# V32F20x_CM33 register map
File version: 1.0.3
CPU: CM33 r0p4, little endian, MPU, FPU, DSP, 3 interrupt priority bits, 8 SAU regions
Registers are 32-bit, read-write, reset 0x0 unless marked. A register's access mark holds for its fields unless they carry their own. Offsets are from the block's base; [hi:lo] are bit positions; {n}, {i} and the like mark numbered series.

## ETMR0 — ETMR0 Peripheral Interface
Base 0x40050800
Same registers: ETMR1 0x40051000, SEC_ETMR0 0x50050800, SEC_ETMR1 0x50051000
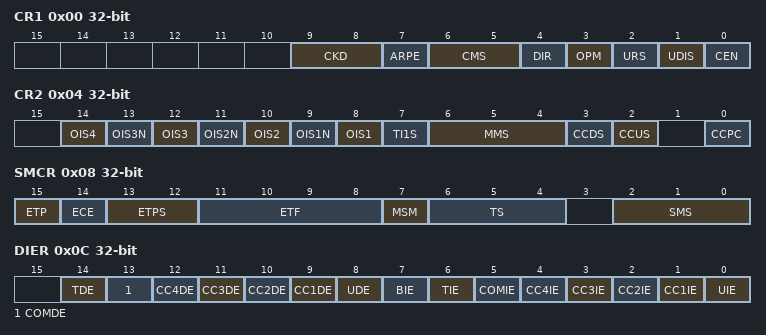
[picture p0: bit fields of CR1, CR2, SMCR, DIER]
0x00 CR1 — ETMR control register 1
  [9:8] CKD — This bit field indicates the division ratio between the timer clock CK_INT frequency and the dead time and sampling clock tDTS used by the dead time generators and the digital filters ETR TIx
  [7] ARPE — 0: ETMR_ARR register is not buffered
  [6:5] CMS — 00 Edge aligned mode
  [4] DIR — 0: Counter used as upcounter
  [3] OPM — 0: Counter is not stopped at update event
  [2] URS — This bit is set and cleared by software to select the UEV event sources
  [1] UDIS — This bit is set and cleared by software to enable disable UEV event generation
  [0] CEN — 0: Counter disabled
0x04 CR2 — ETMR control register 1
  [14] OIS4 — refer to OIS1 bit
  [13] OIS3N — refer to OIS1N bit
  [12] OIS3 — refer to OIS1 bit
  [11] OIS2N — refer to OIS1N bit
  [10] OIS2 — refer to OIS1 bit
  [9] OIS1N — 0: OC1N=0 after a dead-time when MOE=0
  [8] OIS1 — 0 OC1 0 after a dead time if OC1N is implemented when MOE 0
  [7] TI1S — 0: The ETMR_CH1 pin is connected to TI1 input
  [6:4] MMS — These bits allow to select the information to be sent in master mode to slave timers for synchronization TRGO
  [3] CCDS — 0: CCx DMA request sent when CCx event occurs
  [2] CCUS — 0 When capture compare control bits are preloaded CCPC 1 they are updated by setting the COMG bit only
  [0] CCPC — 0: CCxE, CCxNE and OCxM bits are not preloaded
0x08 SMCR — slave mode control register
  [15] ETP — This bit selects whether ETR or ETR is used for trigger operations
  [14] ECE — This bit enables External clock mode 2.
  [13:12] ETPS — External trigger signal ETRP frequency must be at most 1 4 of ETMRCLK frequency
  [11:8] ETF — This bit field then defines the frequency used to sample ETRP signal and the length of the digital filter applied to ETRP
  [7] MSM — 0: No action
  [6:4] TS — This bit field selects the trigger input to be used to synchronize the counter
  [2:0] SMS — When external signals are selected the active edge of the trigger signal TRGI is linked to the polarity selected on the external input see Input Control register and Control register description
0x0C DIER — DMA/interrupt enable register
  [14] TDE — 0: Trigger DMA request disabled
  [13] COMDE — 0: COM DMA request disabled
  [n+8] CC{n}DE (n=1..4) — 0: CC{n} DMA request disabled
  [8] UDE — 0: Update DMA request disabled
  [7] BIE — 0: Break interrupt disabled
  [6] TIE — 0: Trigger interrupt disabled
  [5] COMIE — 0: COM interrupt disabled
  [n] CC{n}IE (n=1..4) — 0: CC{n} interrupt disabled
  [0] UIE — Update interrupt enable
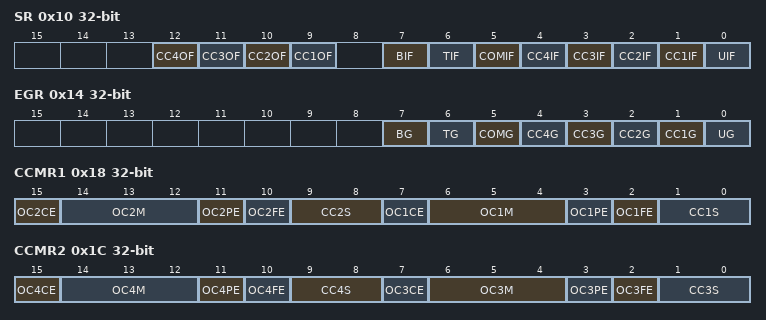
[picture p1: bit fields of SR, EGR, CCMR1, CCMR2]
0x10 SR — status register
  [12] CC4OF — refer to CC1OF description
  [11] CC3OF — refer to CC1OF description
  [10] CC2OF — refer to CC1OF description
  [9] CC1OF — This flag is set by hardware only when the corresponding channel is configured in input capture mode
  [7] BIF — This flag is set by hardware as soon as the break input goes active
  [6] TIF — This flag is set by hardware on trigger event active edge detected on TRGI input when the slave mode controller is enabled in all modes but gated mode both edges in case gated mode is selected
  [5] COMIF — This flag is set by hardware on COM event when Capture compare Control bits CCxE CCxNE OCxM have been updated
  [4] CC4IF — refer to CC1IF description
  [3] CC3IF — refer to CC1IF description
  [2] CC2IF — refer to CC1IF description
  [1] CC1IF — If channel CC1 is configured as output:
  [0] UIF — This bit is set by hardware on an update event
0x14 EGR — event generation register
  [7] BG — This bit is set by software in order to generate an event it is automatically cleared by hardware
  [6] TG — This bit is set by software in order to generate an event it is automatically cleared by hardware
  [5] COMG — This bit can be set by software it is automatically
  [4] CC4G — refer to CC1G description
  [3] CC3G — refer to CC1G description
  [2] CC2G — refer to CC1G description
  [1] CC1G — This bit is set by software in order to generate an event it is automatically cleared by hardware
  [0] UG — This bit can be set by software it is automatically cleared by hardware
0x18 CCMR1 — capture/compare mode register 1
  [15] OC2CE — Output compare 2 clear enable
  [14:12] OC2M — Output compare 2 mode
  [11] OC2PE — Output compare 2 preload enable
  [10] OC2FE — Output compare 2 fast enable
  [9:8] CC2S — This bit field defines the direction of the channel input output as well as the used input
  [7] OC1CE — 0: OC1Ref is not affected by the ETRF Input
  [6:4] OC1M — These bits define the behavior of the output reference signal OC1REF from which OC1 and OC1N are derived
  [3] OC1PE — 0 Preload register on ETMR_CCR1 disabled
  [2] OC1FE — This bit is used to accelerate the effect of an event on the trigger in input on the CC output
  [1:0] CC1S — This bit field defines the direction of the channel input output as well as the used input
0x1C CCMR2 — capture/compare mode register 2
  [15] OC4CE — Output compare 4 clear enable
  [14:12] OC4M — Output compare 4 mode
  [11] OC4PE — Output compare 4 preload enable
  [10] OC4FE — Output compare 4 fast enable
  [9:8] CC4S — This bit field defines the direction of the channel input output as well as the used input
  [7] OC3CE — Output compare 3 clear enable
  [6:4] OC3M — Output compare 3 mode
  [3] OC3PE — Output compare 3 preload enable
  [2] OC3FE — Output compare 3 fast enable
  [1:0] CC3S — This bit field defines the direction of the channel input output as well as the used input
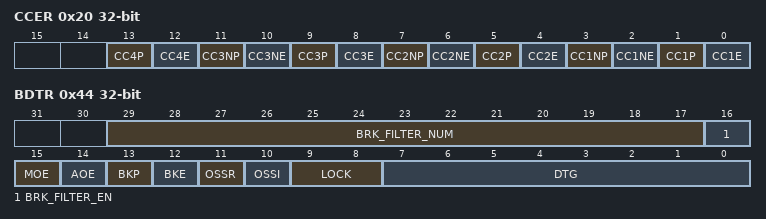
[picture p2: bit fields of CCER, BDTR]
0x20 CCER — capture/compare enable register
  [13] CC4P — refer to CC1P description
  [12] CC4E — refer to CC1E description
  [11] CC3NP — refer to CC1NP description
  [10] CC3NE — refer to CC1NE description
  [9] CC3P — refer to CC1P description
  [8] CC3E — refer to CC1E description
  [7] CC2NP — refer to CC1NP description
  [6] CC2NE — refer to CC1NE description
  [5] CC2P — refer to CC1P description
  [4] CC2E — refer to CC1E description
  [3] CC1NP — Capture/Compare 1 complementary output polarity
  [2] CC1NE — Capture/Compare 1 complementary output enable
  [1] CC1P — CC1 channel configured as output:
  [0] CC1E — CC1 channel configured as output:
0x24 CNT — ETMR counter
  [15:0] CNT — Counter value
0x28 PSC — ETMR prescaler
  [15:0] PSC — The counter clock frequency CK_CNT is equal to fCK_PSC PSC 15 0 1
0x2C ARR — auto-reload register
  [15:0] ARR — ARR is the value to be loaded in the actual auto reload register
0x30 RCR — repetition counter register
  [7:0] REP — These bits allow the user to set up the update rate of the compare registers i
{0x30+4i} CCR{i} (i=1..4) — capture/compare register {i}
  [15:0] CCR{i} — If channel CC{i} is configured as output:
0x44 BDTR — break and dead-time register
  [29:17] BRK_FILTER_NUM — External break signal filter numbers.
  [16] BRK_FILTER_EN — External break signal filter function enable.
  [15] MOE — This bit is cleared asynchronously by hardware as soon as the break input is active
  [14] AOE — 0: MOE can be set only by software
  [13] BKP — 0: Break input BRK is active low
  [12] BKE — 0 Break inputs BRK and CSS clock failure event disabled
  [11] OSSR — This bit is used when MOE 1 on channels having a complementary output which are configured as outputs
  [10] OSSI — This bit is used when MOE 0 on channels configured as outputs
  [9:8] LOCK — These bits offer a write protection against software errors
  [7:0] DTG — This bit field defines the duration of the deadtime inserted between the complementary outputs
